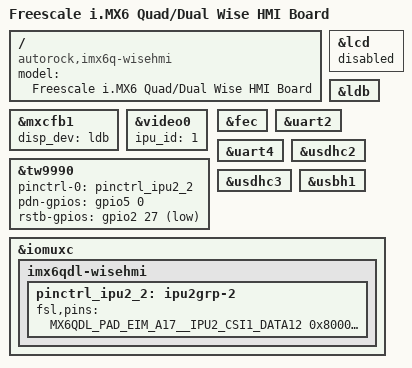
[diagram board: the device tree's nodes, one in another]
/*
 * Copyright 2012=2015 Freescale Semiconductor, Inc.
 * Copyright 2011 Linaro Ltd.
 *
 * The code contained herein is licensed under the GNU General Public
 * License. You may obtain a copy of the GNU General Public License
 * Version 2 or later at the following locations:
 *
 * http://www.opensource.org/licenses/gpl-license.html
 * http://www.gnu.org/copyleft/gpl.html
 */

/dts-v1/;

#include "imx6q.dtsi"
#include "imx6qdl-wisehmi.dtsi"

/ {
	model = "Freescale i.MX6 Quad/Dual Wise HMI Board";
	compatible = "autorock,imx6q-wisehmi", "autorock,imx6qdl-wisehmi", "fsl,imx6q";
};

&lcd {
	status = "disabled";
};

&ldb {
	status = "okay";
};

&mxcfb1 {
	disp_dev = "ldb";
	status = "okay";
};

&video0{
	ipu_id = <1>;
};

&tw9990{
	pinctrl-0 = <&pinctrl_ipu2_2>;
	pdn-gpios = <&gpio5 0 GPIO_ACTIVE_HIGH>;
	rstb-gpios = <&gpio2 27 GPIO_ACTIVE_LOW>;
};

&fec {
	status = "okay";
};

&uart2 {
	status = "okay";
};

&uart4 {
	status = "okay";
};

&usdhc2 {
	status = "okay";
};

&usdhc3 {
	status = "okay";
};

/*&flexcan1 {
	status = "okay";
};

&flexcan2 {
	status = "okay";
};*/

&usbh1 {
	status = "okay";
};

&iomuxc {
	imx6qdl-wisehmi {
		pinctrl_ipu2_2: ipu2grp-2 { /* parallel camera */
			fsl,pins = <
				MX6QDL_PAD_EIM_A17__IPU2_CSI1_DATA12    0x80000000
				MX6QDL_PAD_EIM_A18__IPU2_CSI1_DATA13	0x80000000 
				MX6QDL_PAD_EIM_A19__IPU2_CSI1_DATA14	0x80000000 
				MX6QDL_PAD_EIM_A20__IPU2_CSI1_DATA15	0x80000000 
				MX6QDL_PAD_EIM_A21__IPU2_CSI1_DATA16	0x80000000 
				MX6QDL_PAD_EIM_A22__IPU2_CSI1_DATA17	0x80000000 
				MX6QDL_PAD_EIM_A23__IPU2_CSI1_DATA18	0x80000000 
				MX6QDL_PAD_EIM_A24__IPU2_CSI1_DATA19	0x80000000 
				MX6QDL_PAD_EIM_A16__IPU2_CSI1_PIXCLK	0x80000000 
				MX6QDL_PAD_EIM_DA11__IPU2_CSI1_HSYNC	0x80000000 
				MX6QDL_PAD_EIM_DA12__IPU2_CSI1_VSYNC	0x80000000
			
				/* PDN */
				/*MX6QDL_PAD_SD1_CMD__GPIO1_IO18          0x80000000*/
				/* RSTB */
				/*MX6QDL_PAD_GPIO_7__GPIO1_IO07           0x80000000*/
				/* INTREQ */
				/*MX6QDL_PAD_SD1_DAT3__GPIO1_IO21         0x80000000*/
				/* MPOUT */
				/*MX6QDL_PAD_SD1_DAT2__GPIO1_IO19         0x80000000*/

				/* PDN */
				MX6QDL_PAD_EIM_WAIT__GPIO5_IO00	0x80000000
				/* RSTB */
				MX6QDL_PAD_EIM_LBA__GPIO2_IO27		0x80000000
				/* INTREQ */
				MX6QDL_PAD_EIM_EB0__GPIO2_IO28		0x80000000
				/* MPOUT */
				MX6QDL_PAD_EIM_EB3__GPIO2_IO31		0x80000000
			>;
		};
	};
};
